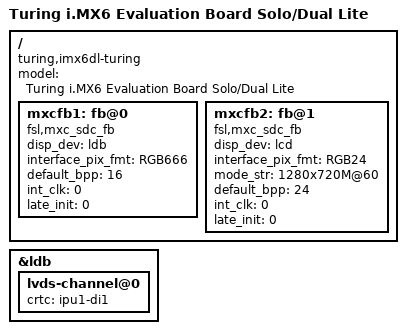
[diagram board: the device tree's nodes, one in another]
/*
 * Copyright (C) 2016 Turing Computer.
 */
/dts-v1/;

#include "imx6dl-turing.dtsi"
#include "imx6qdl-turing-eval.dtsi"

/ {
	model = "Turing i.MX6 Evaluation Board Solo/Dual Lite";
	compatible = "turing,imx6dl-turing", "fsl,imx6dl";
	
	mxcfb1: fb@0 {
		compatible = "fsl,mxc_sdc_fb";
		disp_dev = "ldb";
		interface_pix_fmt = "RGB666";
		default_bpp = <16>;
		int_clk = <0>;
		late_init = <0>;
		status = "okay";
	};

	mxcfb2: fb@1 {
		compatible = "fsl,mxc_sdc_fb";
		disp_dev = "lcd";
		interface_pix_fmt = "RGB24";
		mode_str ="1280x720M@60";
		default_bpp = <24>;
		int_clk = <0>;
		late_init = <0>;
		status = "okay"; 
	};

};

&ldb {
	lvds-channel@0 {
		crtc = "ipu1-di1";
	};
};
